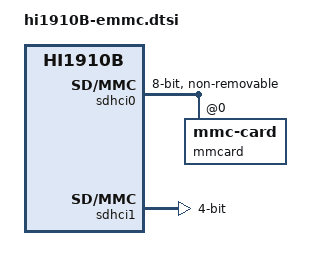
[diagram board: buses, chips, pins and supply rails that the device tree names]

sdhci0: sdhci0@82000000 { //emmc
 	compatible = "hisilicon,sdhci_emmc";
	reg = <0x0 0x82000000 0x0 0x10000>,
		<0x0 0x820e0000 0x0 0x10000>;
	reg-names = "sdhci", "phy";
	interrupt-parent = <&mbigen_emmc>;
	interrupts = <916 0x4>;
	bus-width = <0x8>; // hs400 只支持8bit
	host_id = <0x0>;
	non-removable;
	max-frequency = <200000000>;
	clock-frequency = <200000000>;
	no-sdio;
	no-sd;
	mmc-ddr-1_8v;
	mmc-hs200-1_8v;
	mmc-hs400-1_8v;
	mmc_ddr52_tx_delay = <0x2 0x0>;
	mmc_hs200_tx_delay = <0x8 0x0>;
	mmc_hs400_tx_delay = <0x4 0x30>;
	//[clk_src] [clk_dly_sample] [clk_dly_drv] [clk_div] [sample_mode] [max_clk] [timing_cfg]
	timing_0_cfg = <4000000 0x6 0x6 0x0 0x0 4000000 1 0x23 0x1 0x44 0x44 0x2 0x0 0x0 0x20>;
	timing_1_cfg = <200000000 0x7 0x6 0xf 0x0 200000000 1 0x23 0x1 0x44 0x44 0x2 0x0 0x0 0x20>;
	timing_2_cfg = <1200000000 0x7 0x6 0x5 0x0 200000000 1 0x23 0x1 0x44 0x44 0x2 0x0 0x0 0x20>;
	timing_3_cfg = <1200000000 0x7 0x6 0x5 0x0 200000000 1 0x23 0x1 0x44 0x44 0x2 0x0 0x0 0x20>;
	timing_4_cfg = <1200000000 0x7 0x6 0x5 0x0 200000000 1 0x23 0x1 0x44 0x44 0x2 0x0 0x0 0x20>;
	timing_5_cfg = <1200000000 0x6 0x6 0x5 0x1 200000000 0 0x25 0x4 0x48 0x42 0x4 0x0 0x0 0x20>;
	timing_6_cfg = <1200000000 0x6 0x6 0x5 0x1 200000000 0 0x25 0x4 0x48 0x42 0x4 0x0 0x0 0x20>;
	timing_7_cfg = <1200000000 0x6 0x6 0x5 0x1 200000000 0 0x25 0x4 0x48 0x42 0x4 0x0 0x0 0x20>;
	timing_8_cfg = <200000000 0x0 0x17 0xf 0x1 200000000 1 0x25 0x3 0x48 0x48 0x4 0x0 0x0 0x20>;
	timing_9_cfg = <200000000 0x0 0x17 0xf 0x1 200000000 1 0x25 0x3 0x48 0x48 0x4 0x0 0x0 0x20>;
	timing_10_cfg = <200000000 0x0 0x17 0xf 0x1 200000000 1 0x25 0x3 0x48 0x48 0x4 0x0 0x0 0x20>;
	#address-cells = <0x1>;
	#size-cells = <0x0>;
	mmcard@0 {
		reg = <0x0>;
		compatible = "mmc-card";
		broken-hpi;
	};
};

sdhci1: sdhci1@82010000 {  // sd
	compatible = "hisilicon,sdhci_sd";
	reg = <0x0 0x82010000 0x0 0x10000>;
	interrupt-parent = <&mbigen_sd>;
	interrupts = <917 4>;
	bus-width = <4>;
	host_id = <0>;
	no-sdio;
	no-mmc;
	max-frequency =<200000000>;
	clock-frequency = <1200000000>;
	cd-gpio = <&gpio3 8 0>;
	cd-inverted;
	wp-inverted; /*sd卡需要配置这个 否则会被设置为只读*/
	timing_0_cfg = <4000000 0x6 0x6 0x0 0x0 4000000 0 0x23 0x0 0x44 0x42 0x1 0x1 0x2 0x8>;
	timing_1_cfg = <200000000 0x7 0x6 0xf 0x0 200000000 1 0x23 0x1 0x44 0x44 0x2 0x0 0x0 0x20>;
	timing_2_cfg = <1200000000 0x7 0x6 0x5 0x0 200000000 1 0x23 0x1 0x44 0x44 0x2 0x0 0x0 0x20>;
	timing_3_cfg = <1200000000 0x7 0x6 0x5 0x0 200000000 1 0x23 0x1 0x44 0x44 0x2 0x0 0x0 0x20>;
	timing_4_cfg = <1200000000 0x7 0x6 0x5 0x0 200000000 1 0x23 0x1 0x44 0x44 0x2 0x0 0x0 0x20>;
	timing_5_cfg = <1200000000 0x6 0x6 0x5 0x1 200000000 0 0x25 0x4 0x48 0x42 0x4 0x0 0x0 0x20>;
	timing_6_cfg = <1200000000 0x6 0x6 0x5 0x1 200000000 0 0x25 0x4 0x48 0x42 0x4 0x0 0x0 0x20>;
	timing_7_cfg = <1200000000 0x6 0x6 0x5 0x1 200000000 0 0x25 0x4 0x48 0x42 0x4 0x0 0x0 0x20>;
	timing_8_cfg = <200000000 0x0 0x17 0xf 0x1 200000000 1 0x25 0x3 0x48 0x48 0x4 0x0 0x0 0x20>;
	timing_9_cfg = <200000000 0x0 0x17 0xf 0x1 200000000 1 0x25 0x3 0x48 0x48 0x4 0x0 0x0 0x20>;
	timing_10_cfg = <200000000 0x0 0x17 0xf 0x1 200000000 1 0x25 0x3 0x48 0x48 0x4 0x0 0x0 0x20>;
};

aliases {
	mmc0 = &sdhci0; // emmc
	mmc1 = &sdhci1; // sd
	//mmc2 = &sdhci2; // sdio和sd属一个控制器 二选一
};
